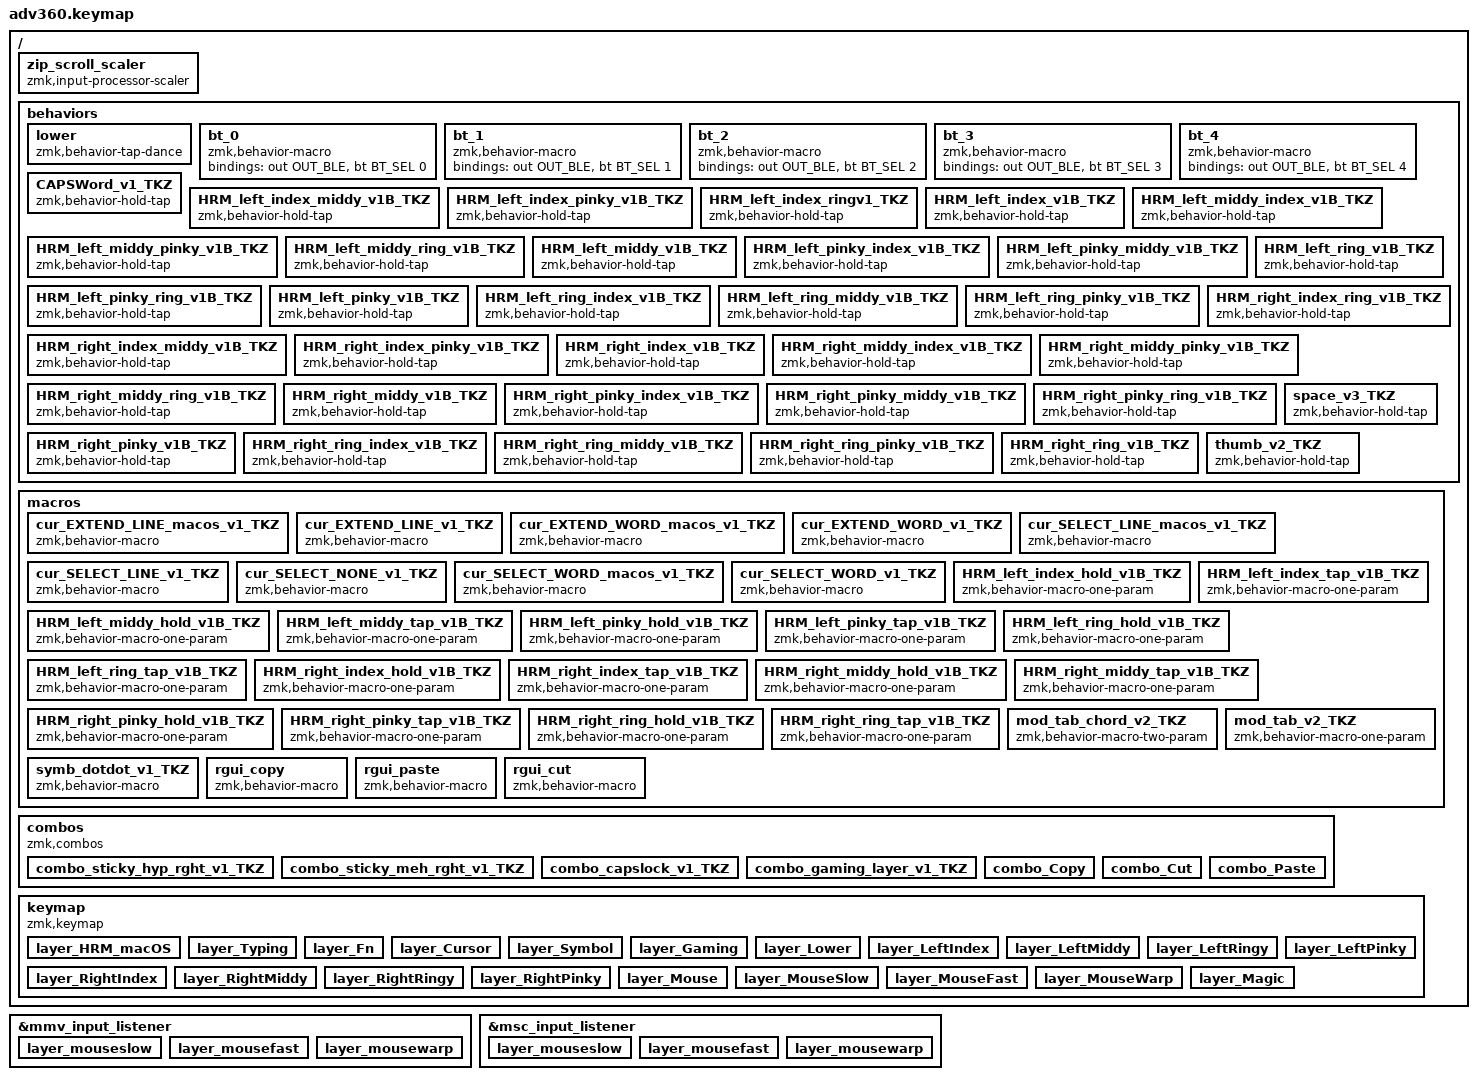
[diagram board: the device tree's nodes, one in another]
/*
 * GENERATED by scripts/glove80_to_adv360.py from "TailorKey v4.2i - macOS Bilateral but my".
 * Do not edit by hand: change the Glove80 layout or the script and regenerate.
 */

#include <behaviors.dtsi>
#include <input/processors.dtsi>
#include <dt-bindings/zmk/keys.h>
#include <dt-bindings/zmk/bt.h>
#include <dt-bindings/zmk/outputs.h>
#include <dt-bindings/zmk/rgb.h>
#include <dt-bindings/zmk/backlight.h>
#include <dt-bindings/zmk/pointing.h>
#include <dt-bindings/zmk/stp.h>

/ {
    /* MoErgo-only; Kinesis's ZMK has the x/y scalers but no scroll scaler. */
    /omit-if-no-ref/ zip_scroll_scaler: zip_scroll_scaler {
        compatible = "zmk,input-processor-scaler";
        #input-processor-cells = <2>;
        type = <INPUT_EV_REL>;
        codes = <INPUT_REL_WHEEL INPUT_REL_HWHEEL>;
        track-remainders;
    };
};

&mmv_input_listener {
    layer_mouseslow {
        layers = <16>;
        input-processors = <&zip_xy_scaler 1 9>;
    };
    layer_mousefast {
        layers = <17>;
        input-processors = <&zip_xy_scaler 3 1>;
    };
    layer_mousewarp {
        layers = <18>;
        input-processors = <&zip_xy_scaler 12 1>;
    };
};
&msc_input_listener {
    layer_mouseslow {
        layers = <16>;
        input-processors = <&zip_scroll_scaler 1 9>;
    };
    layer_mousefast {
        layers = <17>;
        input-processors = <&zip_scroll_scaler 3 1>;
    };
    layer_mousewarp {
        layers = <18>;
        input-processors = <&zip_scroll_scaler 12 1>;
    };
};

/ {
    behaviors {
        lower: lower {
            compatible = "zmk,behavior-tap-dance";
            #binding-cells = <0>;
            tapping-term-ms = <200>;
            bindings = <&mo 6>, <&to 6>;
        };
        bt_0: bt_0 {
            compatible = "zmk,behavior-macro";
            #binding-cells = <0>;
            bindings = <&out OUT_BLE>, <&bt BT_SEL 0>;
        };
        bt_1: bt_1 {
            compatible = "zmk,behavior-macro";
            #binding-cells = <0>;
            bindings = <&out OUT_BLE>, <&bt BT_SEL 1>;
        };
        bt_2: bt_2 {
            compatible = "zmk,behavior-macro";
            #binding-cells = <0>;
            bindings = <&out OUT_BLE>, <&bt BT_SEL 2>;
        };
        bt_3: bt_3 {
            compatible = "zmk,behavior-macro";
            #binding-cells = <0>;
            bindings = <&out OUT_BLE>, <&bt BT_SEL 3>;
        };
        bt_4: bt_4 {
            compatible = "zmk,behavior-macro";
            #binding-cells = <0>;
            bindings = <&out OUT_BLE>, <&bt BT_SEL 4>;
        };
        CAPSWord_v1_TKZ: CAPSWord_v1_TKZ {
            compatible = "zmk,behavior-hold-tap";
            #binding-cells = <2>;
            bindings = <&kp>, <&caps_word>;
            tapping-term-ms = <200>;
        };
        HRM_left_index_middy_v1B_TKZ: HRM_left_index_middy_v1B_TKZ {
            compatible = "zmk,behavior-hold-tap";
            #binding-cells = <2>;
            bindings = <&kp>, <&HRM_left_index_tap_v1B_TKZ>;
            tapping-term-ms = <190>;
            flavor = "tap-preferred";
            quick-tap-ms = <300>;
            require-prior-idle-ms = <100>;
            hold-trigger-on-release;
            hold-trigger-key-positions = <7 8 9 10 11 12 13 21 22 23 24 25 26 27 35 36 37 38 39 40 41 42 43 44 45 52 53 54 55 56 57 58 59 65 66 67 68 69 70 71 72 73 74 75>;
        };
        HRM_left_index_pinky_v1B_TKZ: HRM_left_index_pinky_v1B_TKZ {
            compatible = "zmk,behavior-hold-tap";
            #binding-cells = <2>;
            bindings = <&kp>, <&HRM_left_index_tap_v1B_TKZ>;
            tapping-term-ms = <190>;
            flavor = "tap-preferred";
            quick-tap-ms = <300>;
            require-prior-idle-ms = <100>;
            hold-trigger-on-release;
            hold-trigger-key-positions = <7 8 9 10 11 12 13 21 22 23 24 25 26 27 35 36 37 38 39 40 41 42 43 44 45 52 53 54 55 56 57 58 59 65 66 67 68 69 70 71 72 73 74 75>;
        };
        HRM_left_index_ringv1_TKZ: HRM_left_index_ringv1_TKZ {
            compatible = "zmk,behavior-hold-tap";
            #binding-cells = <2>;
            bindings = <&kp>, <&HRM_left_index_tap_v1B_TKZ>;
            tapping-term-ms = <190>;
            flavor = "tap-preferred";
            quick-tap-ms = <300>;
            require-prior-idle-ms = <100>;
            hold-trigger-on-release;
            hold-trigger-key-positions = <7 8 9 10 11 12 13 21 22 23 24 25 26 27 35 36 37 38 39 40 41 42 43 44 45 52 53 54 55 56 57 58 59 65 66 67 68 69 70 71 72 73 74 75>;
        };
        HRM_left_index_v1B_TKZ: HRM_left_index_v1B_TKZ {
            compatible = "zmk,behavior-hold-tap";
            #binding-cells = <2>;
            bindings = <&HRM_left_index_hold_v1B_TKZ>, <&kp>;
            tapping-term-ms = <190>;
            flavor = "tap-preferred";
            quick-tap-ms = <300>;
            require-prior-idle-ms = <100>;
            hold-trigger-on-release;
            hold-trigger-key-positions = <7 8 9 10 11 12 13 21 22 23 24 25 26 27 35 36 37 38 39 40 41 42 43 44 45 52 53 54 55 56 57 58 59 65 66 67 68 69 70 71 72 73 74 75>;
        };
        HRM_left_middy_index_v1B_TKZ: HRM_left_middy_index_v1B_TKZ {
            compatible = "zmk,behavior-hold-tap";
            #binding-cells = <2>;
            bindings = <&kp>, <&HRM_left_middy_tap_v1B_TKZ>;
            tapping-term-ms = <210>;
            flavor = "tap-preferred";
            quick-tap-ms = <300>;
            require-prior-idle-ms = <150>;
            hold-trigger-on-release;
            hold-trigger-key-positions = <7 8 9 10 11 12 13 21 22 23 24 25 26 27 35 36 37 38 39 40 41 42 43 44 45 52 53 54 55 56 57 58 59 65 66 67 68 69 70 71 72 73 74 75>;
        };
        HRM_left_middy_pinky_v1B_TKZ: HRM_left_middy_pinky_v1B_TKZ {
            compatible = "zmk,behavior-hold-tap";
            #binding-cells = <2>;
            bindings = <&kp>, <&HRM_left_middy_tap_v1B_TKZ>;
            tapping-term-ms = <210>;
            flavor = "tap-preferred";
            quick-tap-ms = <300>;
            require-prior-idle-ms = <150>;
            hold-trigger-on-release;
            hold-trigger-key-positions = <7 8 9 10 11 12 13 21 22 23 24 25 26 27 35 36 37 38 39 40 41 42 43 44 45 52 53 54 55 56 57 58 59 65 66 67 68 69 70 71 72 73 74 75>;
        };
        HRM_left_middy_ring_v1B_TKZ: HRM_left_middy_ring_v1B_TKZ {
            compatible = "zmk,behavior-hold-tap";
            #binding-cells = <2>;
            bindings = <&kp>, <&HRM_left_middy_tap_v1B_TKZ>;
            tapping-term-ms = <210>;
            flavor = "tap-preferred";
            quick-tap-ms = <300>;
            require-prior-idle-ms = <150>;
            hold-trigger-on-release;
            hold-trigger-key-positions = <7 8 9 10 11 12 13 21 22 23 24 25 26 27 35 36 37 38 39 40 41 42 43 44 45 52 53 54 55 56 57 58 59 65 66 67 68 69 70 71 72 73 74 75>;
        };
        HRM_left_middy_v1B_TKZ: HRM_left_middy_v1B_TKZ {
            compatible = "zmk,behavior-hold-tap";
            #binding-cells = <2>;
            bindings = <&HRM_left_middy_hold_v1B_TKZ>, <&kp>;
            tapping-term-ms = <210>;
            flavor = "tap-preferred";
            quick-tap-ms = <300>;
            require-prior-idle-ms = <150>;
            hold-trigger-on-release;
            hold-trigger-key-positions = <7 8 9 10 11 12 13 21 22 23 24 25 26 27 35 36 37 38 39 40 41 42 43 44 45 52 53 54 55 56 57 58 59 65 66 67 68 69 70 71 72 73 74 75>;
        };
        HRM_left_pinky_index_v1B_TKZ: HRM_left_pinky_index_v1B_TKZ {
            compatible = "zmk,behavior-hold-tap";
            #binding-cells = <2>;
            bindings = <&kp>, <&HRM_left_pinky_tap_v1B_TKZ>;
            tapping-term-ms = <280>;
            flavor = "tap-preferred";
            quick-tap-ms = <300>;
            require-prior-idle-ms = <150>;
            hold-trigger-on-release;
            hold-trigger-key-positions = <7 8 9 10 11 12 13 21 22 23 24 25 26 27 35 36 37 38 39 40 41 42 43 44 45 52 53 54 55 56 57 58 59 65 66 67 68 69 70 71 72 73 74 75>;
        };
        HRM_left_pinky_middy_v1B_TKZ: HRM_left_pinky_middy_v1B_TKZ {
            compatible = "zmk,behavior-hold-tap";
            #binding-cells = <2>;
            bindings = <&kp>, <&HRM_left_pinky_tap_v1B_TKZ>;
            tapping-term-ms = <280>;
            flavor = "tap-preferred";
            quick-tap-ms = <300>;
            require-prior-idle-ms = <150>;
            hold-trigger-on-release;
            hold-trigger-key-positions = <7 8 9 10 11 12 13 21 22 23 24 25 26 27 35 36 37 38 39 40 41 42 43 44 45 52 53 54 55 56 57 58 59 65 66 67 68 69 70 71 72 73 74 75>;
        };
        HRM_left_pinky_ring_v1B_TKZ: HRM_left_pinky_ring_v1B_TKZ {
            compatible = "zmk,behavior-hold-tap";
            #binding-cells = <2>;
            bindings = <&kp>, <&HRM_left_pinky_tap_v1B_TKZ>;
            tapping-term-ms = <280>;
            flavor = "tap-preferred";
            quick-tap-ms = <300>;
            require-prior-idle-ms = <150>;
            hold-trigger-on-release;
            hold-trigger-key-positions = <7 8 9 10 11 12 13 21 22 23 24 25 26 27 35 36 37 38 39 40 41 42 43 44 45 52 53 54 55 56 57 58 59 65 66 67 68 69 70 71 72 73 74 75>;
        };
        HRM_left_pinky_v1B_TKZ: HRM_left_pinky_v1B_TKZ {
            compatible = "zmk,behavior-hold-tap";
            #binding-cells = <2>;
            bindings = <&HRM_left_pinky_hold_v1B_TKZ>, <&kp>;
            tapping-term-ms = <280>;
            flavor = "tap-preferred";
            quick-tap-ms = <300>;
            require-prior-idle-ms = <150>;
            hold-trigger-on-release;
            hold-trigger-key-positions = <7 8 9 10 11 12 13 21 22 23 24 25 26 27 35 36 37 38 39 40 41 42 43 44 45 52 53 54 55 56 57 58 59 65 66 67 68 69 70 71 72 73 74 75>;
        };
        HRM_left_ring_index_v1B_TKZ: HRM_left_ring_index_v1B_TKZ {
            compatible = "zmk,behavior-hold-tap";
            #binding-cells = <2>;
            bindings = <&kp>, <&HRM_left_ring_tap_v1B_TKZ>;
            tapping-term-ms = <240>;
            flavor = "tap-preferred";
            quick-tap-ms = <300>;
            require-prior-idle-ms = <100>;
            hold-trigger-on-release;
            hold-trigger-key-positions = <7 8 9 10 11 12 13 21 22 23 24 25 26 27 35 36 37 38 39 40 41 42 43 44 45 52 53 54 55 56 57 58 59 65 66 67 68 69 70 71 72 73 74 75>;
        };
        HRM_left_ring_middy_v1B_TKZ: HRM_left_ring_middy_v1B_TKZ {
            compatible = "zmk,behavior-hold-tap";
            #binding-cells = <2>;
            bindings = <&kp>, <&HRM_left_ring_tap_v1B_TKZ>;
            tapping-term-ms = <240>;
            flavor = "tap-preferred";
            quick-tap-ms = <300>;
            require-prior-idle-ms = <150>;
            hold-trigger-on-release;
            hold-trigger-key-positions = <7 8 9 10 11 12 13 21 22 23 24 25 26 27 35 36 37 38 39 40 41 42 43 44 45 52 53 54 55 56 57 58 59 65 66 67 68 69 70 71 72 73 74 75>;
        };
        HRM_left_ring_pinky_v1B_TKZ: HRM_left_ring_pinky_v1B_TKZ {
            compatible = "zmk,behavior-hold-tap";
            #binding-cells = <2>;
            bindings = <&kp>, <&HRM_left_ring_tap_v1B_TKZ>;
            tapping-term-ms = <240>;
            flavor = "tap-preferred";
            quick-tap-ms = <300>;
            require-prior-idle-ms = <150>;
            hold-trigger-on-release;
            hold-trigger-key-positions = <7 8 9 10 11 12 13 21 22 23 24 25 26 27 35 36 37 38 39 40 41 42 43 44 45 52 53 54 55 56 57 58 59 65 66 67 68 69 70 71 72 73 74 75>;
        };
        HRM_left_ring_v1B_TKZ: HRM_left_ring_v1B_TKZ {
            compatible = "zmk,behavior-hold-tap";
            #binding-cells = <2>;
            bindings = <&HRM_left_ring_hold_v1B_TKZ>, <&kp>;
            tapping-term-ms = <240>;
            flavor = "tap-preferred";
            quick-tap-ms = <300>;
            require-prior-idle-ms = <150>;
            hold-trigger-on-release;
            hold-trigger-key-positions = <7 8 9 10 11 12 13 21 22 23 24 25 26 27 35 36 37 38 39 40 41 42 43 44 45 52 53 54 55 56 57 58 59 65 66 67 68 69 70 71 72 73 74 75>;
        };
        HRM_right_index_middy_v1B_TKZ: HRM_right_index_middy_v1B_TKZ {
            compatible = "zmk,behavior-hold-tap";
            #binding-cells = <2>;
            bindings = <&kp>, <&HRM_right_index_tap_v1B_TKZ>;
            tapping-term-ms = <190>;
            flavor = "tap-preferred";
            quick-tap-ms = <300>;
            require-prior-idle-ms = <100>;
            hold-trigger-on-release;
            hold-trigger-key-positions = <0 1 2 3 4 5 6 14 15 16 17 18 19 20 28 29 30 31 32 33 34 35 36 37 38 46 47 48 49 50 51 52 53 60 61 62 63 64 65 66 67 68 69 70>;
        };
        HRM_right_index_pinky_v1B_TKZ: HRM_right_index_pinky_v1B_TKZ {
            compatible = "zmk,behavior-hold-tap";
            #binding-cells = <2>;
            bindings = <&kp>, <&HRM_right_index_tap_v1B_TKZ>;
            tapping-term-ms = <190>;
            flavor = "tap-preferred";
            quick-tap-ms = <300>;
            require-prior-idle-ms = <100>;
            hold-trigger-on-release;
            hold-trigger-key-positions = <0 1 2 3 4 5 6 14 15 16 17 18 19 20 28 29 30 31 32 33 34 35 36 37 38 46 47 48 49 50 51 52 53 60 61 62 63 64 65 66 67 68 69 70>;
        };
        HRM_right_index_ring_v1B_TKZ: HRM_right_index_ring_v1B_TKZ {
            compatible = "zmk,behavior-hold-tap";
            #binding-cells = <2>;
            bindings = <&kp>, <&HRM_right_index_tap_v1B_TKZ>;
            tapping-term-ms = <190>;
            flavor = "tap-preferred";
            quick-tap-ms = <300>;
            require-prior-idle-ms = <100>;
            hold-trigger-on-release;
            hold-trigger-key-positions = <0 1 2 3 4 5 6 14 15 16 17 18 19 20 28 29 30 31 32 33 34 35 36 37 38 46 47 48 49 50 51 52 53 60 61 62 63 64 65 66 67 68 69 70>;
        };
        HRM_right_index_v1B_TKZ: HRM_right_index_v1B_TKZ {
            compatible = "zmk,behavior-hold-tap";
            #binding-cells = <2>;
            bindings = <&HRM_right_index_hold_v1B_TKZ>, <&kp>;
            tapping-term-ms = <190>;
            flavor = "tap-preferred";
            quick-tap-ms = <300>;
            require-prior-idle-ms = <100>;
            hold-trigger-on-release;
            hold-trigger-key-positions = <0 1 2 3 4 5 6 14 15 16 17 18 19 20 28 29 30 31 32 33 34 35 36 37 38 46 47 48 49 50 51 52 53 60 61 62 63 64 65 66 67 68 69 70>;
        };
        HRM_right_middy_index_v1B_TKZ: HRM_right_middy_index_v1B_TKZ {
            compatible = "zmk,behavior-hold-tap";
            #binding-cells = <2>;
            bindings = <&kp>, <&HRM_right_middy_tap_v1B_TKZ>;
            tapping-term-ms = <210>;
            flavor = "tap-preferred";
            quick-tap-ms = <300>;
            require-prior-idle-ms = <150>;
            hold-trigger-on-release;
            hold-trigger-key-positions = <0 1 2 3 4 5 6 14 15 16 17 18 19 20 28 29 30 31 32 33 34 35 36 37 38 46 47 48 49 50 51 52 53 60 61 62 63 64 65 66 67 68 69 70>;
        };
        HRM_right_middy_pinky_v1B_TKZ: HRM_right_middy_pinky_v1B_TKZ {
            compatible = "zmk,behavior-hold-tap";
            #binding-cells = <2>;
            bindings = <&kp>, <&HRM_right_middy_tap_v1B_TKZ>;
            tapping-term-ms = <210>;
            flavor = "tap-preferred";
            quick-tap-ms = <300>;
            require-prior-idle-ms = <150>;
            hold-trigger-on-release;
            hold-trigger-key-positions = <0 1 2 3 4 5 6 14 15 16 17 18 19 20 28 29 30 31 32 33 34 35 36 37 38 46 47 48 49 50 51 52 53 60 61 62 63 64 65 66 67 68 69 70>;
        };
        HRM_right_middy_ring_v1B_TKZ: HRM_right_middy_ring_v1B_TKZ {
            compatible = "zmk,behavior-hold-tap";
            #binding-cells = <2>;
            bindings = <&kp>, <&HRM_right_middy_tap_v1B_TKZ>;
            tapping-term-ms = <210>;
            flavor = "tap-preferred";
            quick-tap-ms = <300>;
            require-prior-idle-ms = <150>;
            hold-trigger-on-release;
            hold-trigger-key-positions = <0 1 2 3 4 5 6 14 15 16 17 18 19 20 28 29 30 31 32 33 34 35 36 37 38 46 47 48 49 50 51 52 53 60 61 62 63 64 65 66 67 68 69 70>;
        };
        HRM_right_middy_v1B_TKZ: HRM_right_middy_v1B_TKZ {
            compatible = "zmk,behavior-hold-tap";
            #binding-cells = <2>;
            bindings = <&HRM_right_middy_hold_v1B_TKZ>, <&kp>;
            tapping-term-ms = <210>;
            flavor = "tap-preferred";
            quick-tap-ms = <300>;
            require-prior-idle-ms = <150>;
            hold-trigger-on-release;
            hold-trigger-key-positions = <0 1 2 3 4 5 6 14 15 16 17 18 19 20 28 29 30 31 32 33 34 35 36 37 38 46 47 48 49 50 51 52 53 60 61 62 63 64 65 66 67 68 69 70>;
        };
        HRM_right_pinky_index_v1B_TKZ: HRM_right_pinky_index_v1B_TKZ {
            compatible = "zmk,behavior-hold-tap";
            #binding-cells = <2>;
            bindings = <&kp>, <&HRM_right_pinky_tap_v1B_TKZ>;
            tapping-term-ms = <280>;
            flavor = "tap-preferred";
            quick-tap-ms = <300>;
            require-prior-idle-ms = <150>;
            hold-trigger-on-release;
            hold-trigger-key-positions = <0 1 2 3 4 5 6 14 15 16 17 18 19 20 28 29 30 31 32 33 34 35 36 37 38 46 47 48 49 50 51 52 53 60 61 62 63 64 65 66 67 68 69 70>;
        };
        HRM_right_pinky_middy_v1B_TKZ: HRM_right_pinky_middy_v1B_TKZ {
            compatible = "zmk,behavior-hold-tap";
            #binding-cells = <2>;
            bindings = <&kp>, <&HRM_right_pinky_tap_v1B_TKZ>;
            tapping-term-ms = <280>;
            flavor = "tap-preferred";
            quick-tap-ms = <300>;
            require-prior-idle-ms = <150>;
            hold-trigger-on-release;
            hold-trigger-key-positions = <0 1 2 3 4 5 6 14 15 16 17 18 19 20 28 29 30 31 32 33 34 35 36 37 38 46 47 48 49 50 51 52 53 60 61 62 63 64 65 66 67 68 69 70>;
        };
        HRM_right_pinky_ring_v1B_TKZ: HRM_right_pinky_ring_v1B_TKZ {
            compatible = "zmk,behavior-hold-tap";
            #binding-cells = <2>;
            bindings = <&kp>, <&HRM_right_pinky_tap_v1B_TKZ>;
            tapping-term-ms = <280>;
            flavor = "tap-preferred";
            quick-tap-ms = <300>;
            require-prior-idle-ms = <150>;
            hold-trigger-on-release;
            hold-trigger-key-positions = <0 1 2 3 4 5 6 14 15 16 17 18 19 20 28 29 30 31 32 33 34 35 36 37 38 46 47 48 49 50 51 52 53 60 61 62 63 64 65 66 67 68 69 70>;
        };
        HRM_right_pinky_v1B_TKZ: HRM_right_pinky_v1B_TKZ {
            compatible = "zmk,behavior-hold-tap";
            #binding-cells = <2>;
            bindings = <&HRM_right_pinky_hold_v1B_TKZ>, <&kp>;
            tapping-term-ms = <280>;
            flavor = "tap-preferred";
            quick-tap-ms = <300>;
            require-prior-idle-ms = <150>;
            hold-trigger-on-release;
            hold-trigger-key-positions = <0 1 2 3 4 5 6 14 15 16 17 18 19 20 28 29 30 31 32 33 34 35 36 37 38 46 47 48 49 50 51 52 53 60 61 62 63 64 65 66 67 68 69 70>;
        };
        HRM_right_ring_index_v1B_TKZ: HRM_right_ring_index_v1B_TKZ {
            compatible = "zmk,behavior-hold-tap";
            #binding-cells = <2>;
            bindings = <&kp>, <&HRM_right_ring_tap_v1B_TKZ>;
            tapping-term-ms = <240>;
            flavor = "tap-preferred";
            quick-tap-ms = <300>;
            require-prior-idle-ms = <150>;
            hold-trigger-on-release;
            hold-trigger-key-positions = <0 1 2 3 4 5 6 14 15 16 17 18 19 20 28 29 30 31 32 33 34 35 36 37 38 46 47 48 49 50 51 52 53 60 61 62 63 64 65 66 67 68 69 70>;
        };
        HRM_right_ring_middy_v1B_TKZ: HRM_right_ring_middy_v1B_TKZ {
            compatible = "zmk,behavior-hold-tap";
            #binding-cells = <2>;
            bindings = <&kp>, <&HRM_right_ring_tap_v1B_TKZ>;
            tapping-term-ms = <240>;
            flavor = "tap-preferred";
            quick-tap-ms = <300>;
            require-prior-idle-ms = <150>;
            hold-trigger-on-release;
            hold-trigger-key-positions = <0 1 2 3 4 5 6 14 15 16 17 18 19 20 28 29 30 31 32 33 34 35 36 37 38 46 47 48 49 50 51 52 53 60 61 62 63 64 65 66 67 68 69 70>;
        };
        HRM_right_ring_pinky_v1B_TKZ: HRM_right_ring_pinky_v1B_TKZ {
            compatible = "zmk,behavior-hold-tap";
            #binding-cells = <2>;
            bindings = <&kp>, <&HRM_right_ring_tap_v1B_TKZ>;
            tapping-term-ms = <240>;
            flavor = "tap-preferred";
            quick-tap-ms = <300>;
            require-prior-idle-ms = <150>;
            hold-trigger-on-release;
            hold-trigger-key-positions = <0 1 2 3 4 5 6 14 15 16 17 18 19 20 28 29 30 31 32 33 34 35 36 37 38 46 47 48 49 50 51 52 53 60 61 62 63 64 65 66 67 68 69 70>;
        };
        HRM_right_ring_v1B_TKZ: HRM_right_ring_v1B_TKZ {
            compatible = "zmk,behavior-hold-tap";
            #binding-cells = <2>;
            bindings = <&HRM_right_ring_hold_v1B_TKZ>, <&kp>;
            tapping-term-ms = <240>;
            flavor = "tap-preferred";
            quick-tap-ms = <300>;
            require-prior-idle-ms = <150>;
            hold-trigger-on-release;
            hold-trigger-key-positions = <0 1 2 3 4 5 6 14 15 16 17 18 19 20 28 29 30 31 32 33 34 35 36 37 38 46 47 48 49 50 51 52 53 60 61 62 63 64 65 66 67 68 69 70>;
        };
        space_v3_TKZ: space_v3_TKZ {
            compatible = "zmk,behavior-hold-tap";
            #binding-cells = <2>;
            bindings = <&mo>, <&kp>;
            tapping-term-ms = <200>;
            flavor = "balanced";
            quick-tap-ms = <150>;
        };
        thumb_v2_TKZ: thumb_v2_TKZ {
            compatible = "zmk,behavior-hold-tap";
            #binding-cells = <2>;
            bindings = <&mo>, <&kp>;
            tapping-term-ms = <200>;
            flavor = "balanced";
            quick-tap-ms = <300>;
        };
    };

    macros {
        cur_EXTEND_LINE_macos_v1_TKZ: cur_EXTEND_LINE_macos_v1_TKZ {
            compatible = "zmk,behavior-macro";
            #binding-cells = <0>;
            wait-ms = <1>;
            tap-ms = <1>;
            bindings = <&kp LG(LS(RIGHT))>;
        };
        cur_EXTEND_LINE_v1_TKZ: cur_EXTEND_LINE_v1_TKZ {
            compatible = "zmk,behavior-macro";
            #binding-cells = <0>;
            wait-ms = <1>;
            tap-ms = <1>;
            bindings = <&kp LS(END)>;
        };
        cur_EXTEND_WORD_macos_v1_TKZ: cur_EXTEND_WORD_macos_v1_TKZ {
            compatible = "zmk,behavior-macro";
            #binding-cells = <0>;
            wait-ms = <1>;
            tap-ms = <1>;
            bindings = <&kp LA(LS(RIGHT))>;
        };
        cur_EXTEND_WORD_v1_TKZ: cur_EXTEND_WORD_v1_TKZ {
            compatible = "zmk,behavior-macro";
            #binding-cells = <0>;
            wait-ms = <1>;
            tap-ms = <1>;
            bindings = <&kp LC(LS(RIGHT))>;
        };
        cur_SELECT_LINE_macos_v1_TKZ: cur_SELECT_LINE_macos_v1_TKZ {
            compatible = "zmk,behavior-macro";
            #binding-cells = <0>;
            wait-ms = <1>;
            tap-ms = <1>;
            bindings = <&kp LG(LEFT)>, <&kp LG(LS(RIGHT))>;
        };
        cur_SELECT_LINE_v1_TKZ: cur_SELECT_LINE_v1_TKZ {
            compatible = "zmk,behavior-macro";
            #binding-cells = <0>;
            wait-ms = <1>;
            tap-ms = <1>;
            bindings = <&kp HOME>, <&kp LS(END)>;
        };
        cur_SELECT_NONE_v1_TKZ: cur_SELECT_NONE_v1_TKZ {
            compatible = "zmk,behavior-macro";
            #binding-cells = <0>;
            wait-ms = <1>;
            tap-ms = <1>;
            bindings = <&kp DOWN>, <&kp UP>, <&kp RIGHT>, <&kp LEFT>;
        };
        cur_SELECT_WORD_macos_v1_TKZ: cur_SELECT_WORD_macos_v1_TKZ {
            compatible = "zmk,behavior-macro";
            #binding-cells = <0>;
            wait-ms = <1>;
            tap-ms = <1>;
            bindings = <&kp LA(LEFT)>, <&kp LA(LS(RIGHT))>;
        };
        cur_SELECT_WORD_v1_TKZ: cur_SELECT_WORD_v1_TKZ {
            compatible = "zmk,behavior-macro";
            #binding-cells = <0>;
            wait-ms = <1>;
            tap-ms = <1>;
            bindings = <&kp LC(LEFT)>, <&kp LC(LS(RIGHT))>;
        };
        HRM_left_index_hold_v1B_TKZ: HRM_left_index_hold_v1B_TKZ {
            compatible = "zmk,behavior-macro-one-param";
            #binding-cells = <1>;
            wait-ms = <0>;
            tap-ms = <0>;
            bindings = <&macro_press>, <&macro_param_1to1>, <&kp A>, <&mo 7>, <&macro_pause_for_release>, <&macro_release>, <&macro_param_1to1>, <&kp A>, <&mo 7>;
        };
        HRM_left_index_tap_v1B_TKZ: HRM_left_index_tap_v1B_TKZ {
            compatible = "zmk,behavior-macro-one-param";
            #binding-cells = <1>;
            wait-ms = <0>;
            tap-ms = <0>;
            bindings = <&macro_release>, <&kp LSHFT>, <&kp RSHFT>, <&kp LALT>, <&kp RALT>, <&kp LCTRL>, <&kp RCTRL>, <&kp LGUI>, <&kp RGUI>, <&macro_tap>, <&kp F>, <&macro_tap>, <&macro_param_1to1>, <&kp A>;
        };
        HRM_left_middy_hold_v1B_TKZ: HRM_left_middy_hold_v1B_TKZ {
            compatible = "zmk,behavior-macro-one-param";
            #binding-cells = <1>;
            wait-ms = <0>;
            tap-ms = <0>;
            bindings = <&macro_press>, <&macro_param_1to1>, <&kp A>, <&mo 8>, <&macro_pause_for_release>, <&macro_release>, <&macro_param_1to1>, <&kp A>, <&mo 8>;
        };
        HRM_left_middy_tap_v1B_TKZ: HRM_left_middy_tap_v1B_TKZ {
            compatible = "zmk,behavior-macro-one-param";
            #binding-cells = <1>;
            wait-ms = <0>;
            tap-ms = <0>;
            bindings = <&macro_release>, <&kp LSHFT>, <&kp RSHFT>, <&kp LALT>, <&kp RALT>, <&kp LCTRL>, <&kp RCTRL>, <&kp LGUI>, <&kp RGUI>, <&macro_tap>, <&kp D>, <&macro_tap>, <&macro_param_1to1>, <&kp A>;
        };
        HRM_left_pinky_hold_v1B_TKZ: HRM_left_pinky_hold_v1B_TKZ {
            compatible = "zmk,behavior-macro-one-param";
            #binding-cells = <1>;
            wait-ms = <0>;
            tap-ms = <0>;
            bindings = <&macro_press>, <&macro_param_1to1>, <&kp A>, <&mo 10>, <&macro_pause_for_release>, <&macro_release>, <&macro_param_1to1>, <&kp A>, <&mo 10>;
        };
        HRM_left_pinky_tap_v1B_TKZ: HRM_left_pinky_tap_v1B_TKZ {
            compatible = "zmk,behavior-macro-one-param";
            #binding-cells = <1>;
            wait-ms = <0>;
            tap-ms = <0>;
            bindings = <&macro_release>, <&kp LSHFT>, <&kp RSHFT>, <&kp LALT>, <&kp RALT>, <&kp LCTRL>, <&kp RCTRL>, <&kp LGUI>, <&kp RGUI>, <&macro_tap>, <&kp A>, <&macro_tap>, <&macro_param_1to1>, <&kp A>;
        };
        HRM_left_ring_hold_v1B_TKZ: HRM_left_ring_hold_v1B_TKZ {
            compatible = "zmk,behavior-macro-one-param";
            #binding-cells = <1>;
            wait-ms = <0>;
            tap-ms = <0>;
            bindings = <&macro_press>, <&macro_param_1to1>, <&kp A>, <&mo 9>, <&macro_pause_for_release>, <&macro_release>, <&macro_param_1to1>, <&kp A>, <&mo 9>;
        };
        HRM_left_ring_tap_v1B_TKZ: HRM_left_ring_tap_v1B_TKZ {
            compatible = "zmk,behavior-macro-one-param";
            #binding-cells = <1>;
            wait-ms = <0>;
            tap-ms = <0>;
            bindings = <&macro_release>, <&kp LSHFT>, <&kp RSHFT>, <&kp LALT>, <&kp RALT>, <&kp LCTRL>, <&kp RCTRL>, <&kp LGUI>, <&kp RGUI>, <&macro_tap>, <&kp S>, <&macro_tap>, <&macro_param_1to1>, <&kp A>;
        };
        HRM_right_index_hold_v1B_TKZ: HRM_right_index_hold_v1B_TKZ {
            compatible = "zmk,behavior-macro-one-param";
            #binding-cells = <1>;
            wait-ms = <0>;
            tap-ms = <0>;
            bindings = <&macro_press>, <&macro_param_1to1>, <&kp A>, <&mo 11>, <&macro_pause_for_release>, <&macro_release>, <&macro_param_1to1>, <&kp A>, <&mo 11>;
        };
        HRM_right_index_tap_v1B_TKZ: HRM_right_index_tap_v1B_TKZ {
            compatible = "zmk,behavior-macro-one-param";
            #binding-cells = <1>;
            wait-ms = <0>;
            tap-ms = <0>;
            bindings = <&macro_release>, <&kp LSHFT>, <&kp RSHFT>, <&kp LALT>, <&kp RALT>, <&kp LCTRL>, <&kp RCTRL>, <&kp LGUI>, <&kp RGUI>, <&macro_tap>, <&kp J>, <&macro_tap>, <&macro_param_1to1>, <&kp A>;
        };
        HRM_right_middy_hold_v1B_TKZ: HRM_right_middy_hold_v1B_TKZ {
            compatible = "zmk,behavior-macro-one-param";
            #binding-cells = <1>;
            wait-ms = <0>;
            tap-ms = <0>;
            bindings = <&macro_press>, <&macro_param_1to1>, <&kp A>, <&mo 12>, <&macro_pause_for_release>, <&macro_release>, <&macro_param_1to1>, <&kp A>, <&mo 12>;
        };
        HRM_right_middy_tap_v1B_TKZ: HRM_right_middy_tap_v1B_TKZ {
            compatible = "zmk,behavior-macro-one-param";
            #binding-cells = <1>;
            wait-ms = <0>;
            tap-ms = <0>;
            bindings = <&macro_release>, <&kp LSHFT>, <&kp RSHFT>, <&kp LALT>, <&kp RALT>, <&kp LCTRL>, <&kp RCTRL>, <&kp LGUI>, <&kp RGUI>, <&macro_tap>, <&kp K>, <&macro_tap>, <&macro_param_1to1>, <&kp A>;
        };
        HRM_right_pinky_hold_v1B_TKZ: HRM_right_pinky_hold_v1B_TKZ {
            compatible = "zmk,behavior-macro-one-param";
            #binding-cells = <1>;
            wait-ms = <0>;
            tap-ms = <0>;
            bindings = <&macro_press>, <&macro_param_1to1>, <&kp A>, <&mo 14>, <&macro_pause_for_release>, <&macro_release>, <&macro_param_1to1>, <&kp A>, <&mo 14>;
        };
        HRM_right_pinky_tap_v1B_TKZ: HRM_right_pinky_tap_v1B_TKZ {
            compatible = "zmk,behavior-macro-one-param";
            #binding-cells = <1>;
            wait-ms = <0>;
            tap-ms = <0>;
            bindings = <&macro_release>, <&kp LSHFT>, <&kp RSHFT>, <&kp LALT>, <&kp RALT>, <&kp LCTRL>, <&kp RCTRL>, <&kp LGUI>, <&kp RGUI>, <&macro_tap>, <&kp SEMI>, <&macro_tap>, <&macro_param_1to1>, <&kp A>;
        };
        HRM_right_ring_hold_v1B_TKZ: HRM_right_ring_hold_v1B_TKZ {
            compatible = "zmk,behavior-macro-one-param";
            #binding-cells = <1>;
            wait-ms = <0>;
            tap-ms = <0>;
            bindings = <&macro_press>, <&macro_param_1to1>, <&kp A>, <&mo 13>, <&macro_pause_for_release>, <&macro_release>, <&macro_param_1to1>, <&kp A>, <&mo 13>;
        };
        HRM_right_ring_tap_v1B_TKZ: HRM_right_ring_tap_v1B_TKZ {
            compatible = "zmk,behavior-macro-one-param";
            #binding-cells = <1>;
            wait-ms = <0>;
            tap-ms = <0>;
            bindings = <&macro_release>, <&kp LSHFT>, <&kp RSHFT>, <&kp LALT>, <&kp RALT>, <&kp LCTRL>, <&kp RCTRL>, <&kp LGUI>, <&kp RGUI>, <&macro_tap>, <&kp L>, <&macro_tap>, <&macro_param_1to1>, <&kp A>;
        };
        mod_tab_chord_v2_TKZ: mod_tab_chord_v2_TKZ {
            compatible = "zmk,behavior-macro-two-param";
            #binding-cells = <2>;
            wait-ms = <0>;
            tap-ms = <0>;
            bindings = <&macro_press>, <&macro_param_2to1>, <&mo 0>, <&macro_press>, <&macro_param_1to1>, <&mod_tab_v2_TKZ 0>, <&macro_pause_for_release>, <&macro_release>, <&macro_param_1to1>, <&mod_tab_v2_TKZ 0>, <&macro_release>, <&macro_param_2to1>, <&mo 0>;
        };
        mod_tab_v2_TKZ: mod_tab_v2_TKZ {
            compatible = "zmk,behavior-macro-one-param";
            #binding-cells = <1>;
            wait-ms = <0>;
            tap-ms = <0>;
            bindings = <&macro_press>, <&macro_param_1to1>, <&kp 0>, <&macro_tap>, <&kp TAB>, <&macro_pause_for_release>, <&macro_release>, <&macro_param_1to1>, <&kp 0>;
        };
        symb_dotdot_v1_TKZ: symb_dotdot_v1_TKZ {
            compatible = "zmk,behavior-macro";
            #binding-cells = <0>;
            wait-ms = <0>;
            tap-ms = <0>;
            bindings = <&macro_tap>, <&kp DOT>, <&kp DOT>;
        };
        rgui_copy: rgui_copy {
            compatible = "zmk,behavior-macro";
            #binding-cells = <0>;
            bindings = <&macro_press>, <&kp RGUI>, <&macro_tap>, <&kp C>, <&macro_release>, <&kp RGUI>;
        };
        rgui_paste: rgui_paste {
            compatible = "zmk,behavior-macro";
            #binding-cells = <0>;
            bindings = <&macro_press>, <&kp RGUI>, <&macro_tap>, <&kp V>, <&macro_release>, <&kp RGUI>;
        };
        rgui_cut: rgui_cut {
            compatible = "zmk,behavior-macro";
            #binding-cells = <0>;
            bindings = <&macro_press>, <&kp RGUI>, <&macro_tap>, <&kp X>, <&macro_release>, <&kp RGUI>;
        };
    };

    combos {
        compatible = "zmk,combos";
        combo_sticky_hyp_rght_v1_TKZ {
            bindings = <&sk LG(LA(LC(LSHFT)))>;
            key-positions = <38 70>;
            timeout-ms = <50>;
            layers = <0>;
        };
        combo_sticky_meh_rght_v1_TKZ {
            bindings = <&sk LA(LC(LSHFT))>;
            key-positions = <69 70>;
            timeout-ms = <50>;
            layers = <0>;
        };
        combo_capslock_v1_TKZ {
            bindings = <&kp CAPS>;
            key-positions = <35 38>;
            timeout-ms = <50>;
            layers = <0>;
        };
        combo_gaming_layer_v1_TKZ {
            bindings = <&tog 5>;
            key-positions = <51 64>;
            timeout-ms = <50>;
        };
        combo_Copy {
            bindings = <&rgui_copy>;
            key-positions = <48 49>;
            timeout-ms = <50>;
        };
        combo_Cut {
            bindings = <&rgui_cut>;
            key-positions = <48 50>;
            timeout-ms = <50>;
        };
        combo_Paste {
            bindings = <&rgui_paste>;
            key-positions = <49 50>;
            timeout-ms = <50>;
        };
    };

    keymap {
        compatible = "zmk,keymap";
        layer_HRM_macOS {
            display-name = "HRM_macOS";
            bindings = <
            &kp EQUAL  &kp N1  &kp N2  &kp N3  &kp N4  &kp N5  &kp C_PREV  &kp C_VOL_UP  &kp N6  &kp N7  &kp N8  &kp N9  &kp N0  &kp MINUS
            &kp ESC  &kp Q  &kp W  &kp E  &kp R  &kp T  &kp C_PP  &kp C_VOL_DN  &kp Y  &kp U  &kp I  &kp O  &kp P  &kp EQUAL
            &kp TAB  &HRM_left_pinky_v1B_TKZ LCTRL A  &HRM_left_ring_v1B_TKZ LALT S  &HRM_left_middy_v1B_TKZ LGUI D  &HRM_left_index_v1B_TKZ LSHFT F  &kp G  &kp C_NEXT  &CAPSWord_v1_TKZ LSHFT 0  &kp LGUI  &kp RGUI  &CAPSWord_v1_TKZ RSHFT 0  &kp C_MUTE  &kp H  &HRM_right_index_v1B_TKZ LSHFT J  &HRM_right_middy_v1B_TKZ LGUI K  &HRM_right_ring_v1B_TKZ LALT L  &HRM_right_pinky_v1B_TKZ LCTRL SEMI  &kp SQT
            &kp BSLH  &kp Z  &kp X  &kp C  &kp V  &kp B  &lower  &kp LCTRL  &kp N  &kp M  &kp COMMA  &kp DOT  &kp FSLH  &kp MINUS
            &mo 19  &kp HOME  &kp END  &kp LEFT  &kp RIGHT  &thumb_v2_TKZ 2 RET  &thumb_v2_TKZ 3 SPACE  &kp TAB  &kp ESC  &thumb_v2_TKZ 15 BSPC  &space_v3_TKZ 4 DEL  &kp UP  &kp DOWN  &kp LBKT  &kp RBKT  &kp GRAVE
            >;
        };
        layer_Typing {
            display-name = "Typing";
            bindings = <
            &trans  &trans  &trans  &trans  &trans  &trans  &trans  &trans  &trans  &trans  &trans  &trans  &trans  &trans
            &trans  &trans  &trans  &trans  &trans  &trans  &trans  &trans  &trans  &trans  &trans  &trans  &trans  &trans
            &trans  &kp A  &kp S  &kp D  &kp F  &trans  &trans  &trans  &trans  &trans  &trans  &trans  &trans  &kp J  &kp K  &kp L  &kp SEMI  &trans
            &trans  &trans  &trans  &trans  &trans  &trans  &trans  &trans  &trans  &trans  &trans  &trans  &trans  &trans
            &trans  &trans  &trans  &trans  &trans  &trans  &trans  &trans  &trans  &trans  &trans  &trans  &trans  &trans  &trans  &trans
            >;
        };
        layer_Fn {
            display-name = "Fn";
            bindings = <
            &none  &none  &none  &none  &none  &none  &none  &none  &none  &none  &none  &none  &none  &none
            &none  &none  &none  &none  &none  &none  &none  &none  &kp F12  &kp F7  &kp F8  &kp F9  &none  &none
            &none  &none  &none  &none  &none  &none  &none  &none  &none  &none  &none  &none  &kp F11  &kp F4  &kp F5  &kp F6  &none  &none
            &none  &none  &none  &none  &none  &none  &none  &none  &kp F10  &kp F1  &kp F2  &kp F3  &none  &none
            &none  &none  &none  &none  &none  &none  &none  &none  &none  &none  &none  &none  &none  &none  &none  &none
            >;
        };
        layer_Cursor {
            display-name = "Cursor";
            bindings = <
            &none  &kp ESC  &kp INS  &kp LS(TAB)  &kp DEL  &none  &none  &none  &none  &none  &none  &none  &none  &none
            &none  &kp RET  &kp SPACE  &kp TAB  &kp BSPC  &kp LG(X)  &none  &none  &kp LG(X)  &kp LS(TAB)  &kp LG(Z)  &kp LG(LS(Z))  &kp TAB  &none
            &sk LSHFT  &kp LCTRL  &kp LALT  &kp LGUI  &kp LSHFT  &kp LG(C)  &none  &mod_tab_v2_TKZ LGUI  &mod_tab_v2_TKZ LALT  &cur_EXTEND_LINE_macos_v1_TKZ  &cur_EXTEND_WORD_macos_v1_TKZ  &none  &kp LEFT  &kp DOWN  &kp UP  &kp RIGHT  &none  &sk RSHFT
            &kp LG(L)  &kp LG(A)  &cur_SELECT_LINE_macos_v1_TKZ  &cur_SELECT_WORD_macos_v1_TKZ  &kp LG(F)  &kp LG(V)  &kp PSCRN  &cur_SELECT_NONE_v1_TKZ  &kp LG(V)  &kp HOME  &kp PG_UP  &kp PG_DN  &kp END  &kp LG(L)
            &kp LG(K)  &kp LG(Z)  &kp LG(LS(Z))  &kp LG(LS(G))  &kp LG(G)  &none  &mod_tab_v2_TKZ LCTRL  &kp LG(F3)  &kp LG(A)  &cur_SELECT_LINE_macos_v1_TKZ  &cur_SELECT_WORD_macos_v1_TKZ  &kp LG(F)  &kp LG(LS(G))  &kp LG(G)  &kp LC(H)  &kp LG(K)
            >;
        };
        layer_Symbol {
            display-name = "Symbol";
            bindings = <
            &kp GRAVE  &kp COMMA  &kp LS(N9)  &kp LS(N0)  &kp SEMI  &kp DOT  &none  &none  &none  &none  &none  &none  &none  &none
            &kp LS(N1)  &kp LBKT  &kp LS(LBKT)  &kp LS(RBKT)  &kp RBKT  &kp LS(FSLH)  &none  &none  &kp GRAVE  &kp DEL  &kp LS(TAB)  &kp INS  &kp ESC  &none
            &kp LS(N3)  &kp LS(N6)  &kp EQUAL  &kp LS(MINUS)  &kp LS(N4)  &kp LS(N8)  &none  &kp BSLH  &kp DOT  &none  &none  &none  &kp LS(SINGLE_QUOTE)  &kp BSPC  &kp TAB  &kp SPACE  &kp RET  &none
            &kp LS(GRAVE)  &kp LS(COMMA)  &kp LS(BSLH)  &kp MINUS  &kp LS(DOT)  &kp FSLH  &kp LS(N8)  &none  &kp SQT  &sk RSHFT  &sk RCTRL  &sk RALT  &sk RGUI  &none
            &symb_dotdot_v1_TKZ  &kp LS(N7)  &kp SQT  &kp LS(SINGLE_QUOTE)  &kp LS(EQUAL)  &kp LS(N5)  &kp LS(SEMI)  &kp LS(N2)  &none  &none  &none  &none  &none  &none  &none  &none
            >;
        };
        layer_Gaming {
            display-name = "Gaming";
            bindings = <
            &kp M  &kp N6  &kp N7  &kp N8  &kp N9  &kp N0  &none  &none  &kp F6  &kp F7  &kp F8  &kp F9  &kp F10  &kp F11
            &kp I  &kp N1  &kp N2  &kp N3  &kp N4  &kp N5  &none  &none  &kp Y  &kp U  &kp I  &kp O  &kp P  &kp F12
            &kp T  &kp TAB  &kp Q  &kp W  &kp E  &kp R  &none  &kp LSHFT  &kp LALT  &kp UP  &kp RET  &none  &kp H  &kp J  &kp K  &kp L  &kp SEMI  &kp SQT
            &kp G  &kp LSHFT  &kp A  &kp S  &kp D  &kp F  &kp V  &kp ESC  &kp N  &kp M  &kp COMMA  &kp DOT  &kp FSLH  &kp BSLH
            &kp B  &kp LCTRL  &kp Z  &kp X  &kp C  &kp SPACE  &kp LCTRL  &kp RET  &kp LEFT  &kp DOWN  &kp RIGHT  &kp MINUS  &kp LBKT  &kp RBKT  &kp EQUAL  &kp GRAVE
            >;
        };
        layer_Lower {
            display-name = "Lower";
            bindings = <
            &trans  &none  &none  &none  &none  &kp HOME  &kp C_BRI_UP  &none  &kp LS(N9)  &kp KP_NUM  &kp EQUAL  &kp KP_SLASH  &kp KP_MULTIPLY  &kp PRINTSCREEN
            &trans  &none  &none  &kp UP_ARROW  &none  &kp END  &kp C_BRI_DN  &none  &kp LS(N0)  &kp KP_N7  &kp KP_N8  &kp KP_N9  &kp KP_MINUS  &kp SCROLLLOCK
            &trans  &none  &kp LEFT_ARROW  &kp DOWN_ARROW  &kp RIGHT_ARROW  &kp PG_UP  &kp PAUSE_BREAK  &trans  &trans  &trans  &trans  &none  &kp LS(N5)  &kp KP_N4  &kp KP_N5  &kp KP_N6  &kp KP_PLUS  &none
            &trans  &kp K_APP  &none  &kp F11  &kp F12  &kp PG_DN  &to 0  &trans  &kp COMMA  &kp KP_N1  &kp KP_N2  &kp KP_N3  &kp KP_ENTER  &trans
            &mo 19  &kp CAPS  &kp INS  &kp F11  &kp F12  &trans  &trans  &trans  &trans  &trans  &trans  &kp KP_N0  &kp KP_N0  &kp KP_DOT  &kp KP_ENTER  &trans
            >;
        };
        layer_LeftIndex {
            display-name = "LeftIndex";
            bindings = <
            &HRM_left_index_tap_v1B_TKZ EQUAL  &HRM_left_index_tap_v1B_TKZ N1  &HRM_left_index_tap_v1B_TKZ N2  &HRM_left_index_tap_v1B_TKZ N3  &HRM_left_index_tap_v1B_TKZ N4  &HRM_left_index_tap_v1B_TKZ N5  &trans  &trans  &trans  &trans  &trans  &trans  &trans  &trans
            &trans  &HRM_left_index_tap_v1B_TKZ Q  &HRM_left_index_tap_v1B_TKZ W  &HRM_left_index_tap_v1B_TKZ E  &HRM_left_index_tap_v1B_TKZ R  &HRM_left_index_tap_v1B_TKZ T  &trans  &trans  &trans  &trans  &trans  &trans  &trans  &trans
            &trans  &HRM_left_index_pinky_v1B_TKZ LCTRL A  &HRM_left_index_ringv1_TKZ LALT S  &HRM_left_index_middy_v1B_TKZ LGUI D  &none  &HRM_left_index_tap_v1B_TKZ G  &trans  &trans  &trans  &trans  &trans  &trans  &trans  &kp J  &kp K  &kp L  &kp SEMI  &trans
            &trans  &HRM_left_index_tap_v1B_TKZ Z  &HRM_left_index_tap_v1B_TKZ X  &HRM_left_index_tap_v1B_TKZ C  &HRM_left_index_tap_v1B_TKZ V  &HRM_left_index_tap_v1B_TKZ B  &trans  &trans  &trans  &trans  &trans  &trans  &trans  &trans
            &trans  &trans  &trans  &trans  &trans  &trans  &trans  &trans  &trans  &trans  &trans  &trans  &trans  &trans  &trans  &trans
            >;
        };
        layer_LeftMiddy {
            display-name = "LeftMiddy";
            bindings = <
            &HRM_left_middy_tap_v1B_TKZ EQUAL  &HRM_left_middy_tap_v1B_TKZ N1  &HRM_left_middy_tap_v1B_TKZ N2  &HRM_left_middy_tap_v1B_TKZ N3  &HRM_left_middy_tap_v1B_TKZ N4  &HRM_left_middy_tap_v1B_TKZ N5  &trans  &trans  &trans  &trans  &trans  &trans  &trans  &trans
            &trans  &HRM_left_middy_tap_v1B_TKZ Q  &HRM_left_middy_tap_v1B_TKZ W  &HRM_left_middy_tap_v1B_TKZ E  &HRM_left_middy_tap_v1B_TKZ R  &HRM_left_middy_tap_v1B_TKZ T  &trans  &trans  &trans  &trans  &trans  &trans  &trans  &trans
            &trans  &HRM_left_middy_pinky_v1B_TKZ LCTRL A  &HRM_left_middy_ring_v1B_TKZ LALT S  &none  &HRM_left_middy_index_v1B_TKZ LSHFT F  &HRM_left_middy_tap_v1B_TKZ G  &trans  &trans  &trans  &trans  &trans  &trans  &trans  &kp J  &kp K  &kp L  &kp SEMI  &trans
            &trans  &HRM_left_middy_tap_v1B_TKZ Z  &HRM_left_middy_tap_v1B_TKZ X  &HRM_left_middy_tap_v1B_TKZ C  &HRM_left_middy_tap_v1B_TKZ V  &HRM_left_middy_tap_v1B_TKZ B  &trans  &trans  &trans  &trans  &trans  &trans  &trans  &trans
            &trans  &trans  &trans  &trans  &trans  &trans  &trans  &trans  &trans  &trans  &trans  &trans  &trans  &trans  &trans  &trans
            >;
        };
        layer_LeftRingy {
            display-name = "LeftRingy";
            bindings = <
            &HRM_left_ring_tap_v1B_TKZ EQUAL  &HRM_left_ring_tap_v1B_TKZ N1  &HRM_left_ring_tap_v1B_TKZ N2  &HRM_left_ring_tap_v1B_TKZ N3  &HRM_left_ring_tap_v1B_TKZ N4  &HRM_left_ring_tap_v1B_TKZ N5  &trans  &trans  &trans  &trans  &trans  &trans  &trans  &trans
            &trans  &HRM_left_ring_tap_v1B_TKZ Q  &HRM_left_ring_tap_v1B_TKZ W  &HRM_left_ring_tap_v1B_TKZ E  &HRM_left_ring_tap_v1B_TKZ R  &HRM_left_ring_tap_v1B_TKZ T  &trans  &trans  &trans  &trans  &trans  &trans  &trans  &trans
            &trans  &HRM_left_ring_pinky_v1B_TKZ LCTRL A  &none  &HRM_left_ring_middy_v1B_TKZ LGUI D  &HRM_left_ring_index_v1B_TKZ LSHFT F  &HRM_left_ring_tap_v1B_TKZ G  &trans  &trans  &trans  &trans  &trans  &trans  &trans  &kp J  &kp K  &kp L  &kp SEMI  &trans
            &trans  &HRM_left_ring_tap_v1B_TKZ Z  &HRM_left_ring_tap_v1B_TKZ X  &HRM_left_ring_tap_v1B_TKZ C  &HRM_left_ring_tap_v1B_TKZ V  &HRM_left_ring_tap_v1B_TKZ B  &trans  &trans  &trans  &trans  &trans  &trans  &trans  &trans
            &trans  &trans  &trans  &trans  &trans  &trans  &trans  &trans  &trans  &trans  &trans  &trans  &trans  &trans  &trans  &trans
            >;
        };
        layer_LeftPinky {
            display-name = "LeftPinky";
            bindings = <
            &HRM_left_pinky_tap_v1B_TKZ EQUAL  &HRM_left_pinky_tap_v1B_TKZ N1  &HRM_left_pinky_tap_v1B_TKZ N2  &HRM_left_pinky_tap_v1B_TKZ N3  &HRM_left_pinky_tap_v1B_TKZ N4  &HRM_left_pinky_tap_v1B_TKZ N5  &trans  &trans  &trans  &trans  &trans  &trans  &trans  &trans
            &trans  &HRM_left_pinky_tap_v1B_TKZ Q  &HRM_left_pinky_tap_v1B_TKZ W  &HRM_left_pinky_tap_v1B_TKZ E  &HRM_left_pinky_tap_v1B_TKZ R  &HRM_left_pinky_tap_v1B_TKZ T  &trans  &trans  &trans  &trans  &trans  &trans  &trans  &trans
            &trans  &none  &HRM_left_pinky_ring_v1B_TKZ LALT S  &HRM_left_pinky_middy_v1B_TKZ LGUI D  &HRM_left_pinky_index_v1B_TKZ LSHFT F  &HRM_left_pinky_tap_v1B_TKZ G  &trans  &trans  &trans  &trans  &trans  &trans  &trans  &kp J  &kp K  &kp L  &kp SEMI  &trans
            &trans  &HRM_left_pinky_tap_v1B_TKZ Z  &HRM_left_pinky_tap_v1B_TKZ X  &HRM_left_pinky_tap_v1B_TKZ C  &HRM_left_pinky_tap_v1B_TKZ V  &HRM_left_pinky_tap_v1B_TKZ B  &trans  &trans  &trans  &trans  &trans  &trans  &trans  &trans
            &trans  &trans  &trans  &trans  &trans  &trans  &trans  &trans  &trans  &trans  &trans  &trans  &trans  &trans  &trans  &trans
            >;
        };
        layer_RightIndex {
            display-name = "RightIndex";
            bindings = <
            &trans  &trans  &trans  &trans  &trans  &trans  &trans  &trans  &HRM_right_index_tap_v1B_TKZ N6  &HRM_right_index_tap_v1B_TKZ N7  &HRM_right_index_tap_v1B_TKZ N8  &HRM_right_index_tap_v1B_TKZ N9  &HRM_right_index_tap_v1B_TKZ N0  &HRM_right_index_tap_v1B_TKZ MINUS
            &trans  &trans  &trans  &trans  &trans  &trans  &trans  &trans  &HRM_right_index_tap_v1B_TKZ Y  &HRM_right_index_tap_v1B_TKZ U  &HRM_right_index_tap_v1B_TKZ I  &HRM_right_index_tap_v1B_TKZ O  &HRM_right_index_tap_v1B_TKZ P  &HRM_right_index_tap_v1B_TKZ BSLH
            &trans  &kp A  &kp S  &kp D  &kp F  &trans  &trans  &trans  &trans  &trans  &trans  &trans  &HRM_right_index_tap_v1B_TKZ H  &none  &HRM_right_index_middy_v1B_TKZ RGUI K  &HRM_right_index_ring_v1B_TKZ LALT L  &HRM_right_index_pinky_v1B_TKZ LCTRL SEMI  &HRM_right_index_tap_v1B_TKZ SQT
            &trans  &trans  &trans  &trans  &trans  &trans  &trans  &trans  &HRM_right_index_tap_v1B_TKZ N  &HRM_right_index_tap_v1B_TKZ M  &HRM_right_index_tap_v1B_TKZ COMMA  &HRM_right_index_tap_v1B_TKZ DOT  &trans  &trans
            &trans  &trans  &trans  &trans  &trans  &trans  &trans  &trans  &trans  &trans  &trans  &trans  &trans  &trans  &trans  &trans
            >;
        };
        layer_RightMiddy {
            display-name = "RightMiddy";
            bindings = <
            &trans  &trans  &trans  &trans  &trans  &trans  &trans  &trans  &HRM_right_middy_tap_v1B_TKZ N6  &HRM_right_middy_tap_v1B_TKZ N7  &HRM_right_middy_tap_v1B_TKZ N8  &HRM_right_middy_tap_v1B_TKZ N9  &HRM_right_middy_tap_v1B_TKZ N0  &HRM_right_middy_tap_v1B_TKZ MINUS
            &trans  &trans  &trans  &trans  &trans  &trans  &trans  &trans  &HRM_right_middy_tap_v1B_TKZ Y  &HRM_right_middy_tap_v1B_TKZ U  &HRM_right_middy_tap_v1B_TKZ I  &HRM_right_middy_tap_v1B_TKZ O  &HRM_right_middy_tap_v1B_TKZ P  &HRM_right_middy_tap_v1B_TKZ BSLH
            &trans  &kp A  &kp S  &kp D  &kp F  &trans  &trans  &trans  &trans  &trans  &trans  &trans  &HRM_right_middy_tap_v1B_TKZ H  &HRM_right_middy_index_v1B_TKZ RSHFT J  &none  &HRM_right_middy_ring_v1B_TKZ LALT L  &HRM_right_middy_pinky_v1B_TKZ RCTRL SEMI  &HRM_right_middy_tap_v1B_TKZ SQT
            &trans  &trans  &trans  &trans  &trans  &trans  &trans  &trans  &HRM_right_middy_tap_v1B_TKZ N  &HRM_right_middy_tap_v1B_TKZ M  &HRM_right_middy_tap_v1B_TKZ COMMA  &HRM_right_middy_tap_v1B_TKZ DOT  &trans  &trans
            &trans  &trans  &trans  &trans  &trans  &trans  &trans  &trans  &trans  &trans  &trans  &trans  &trans  &trans  &trans  &trans
            >;
        };
        layer_RightRingy {
            display-name = "RightRingy";
            bindings = <
            &trans  &trans  &trans  &trans  &trans  &trans  &trans  &trans  &HRM_right_ring_tap_v1B_TKZ N6  &HRM_right_ring_tap_v1B_TKZ N7  &HRM_right_ring_tap_v1B_TKZ N8  &HRM_right_ring_tap_v1B_TKZ N9  &HRM_right_ring_tap_v1B_TKZ N0  &HRM_right_ring_tap_v1B_TKZ MINUS
            &trans  &trans  &trans  &trans  &trans  &trans  &trans  &trans  &HRM_right_ring_tap_v1B_TKZ Y  &HRM_right_ring_tap_v1B_TKZ U  &HRM_right_ring_tap_v1B_TKZ I  &HRM_right_ring_tap_v1B_TKZ O  &HRM_right_ring_tap_v1B_TKZ P  &HRM_right_ring_tap_v1B_TKZ BSLH
            &trans  &kp A  &kp S  &kp D  &kp F  &trans  &trans  &trans  &trans  &trans  &trans  &trans  &HRM_right_ring_tap_v1B_TKZ H  &HRM_right_ring_index_v1B_TKZ RSHFT J  &HRM_right_ring_middy_v1B_TKZ RGUI K  &none  &HRM_right_ring_pinky_v1B_TKZ RCTRL SEMI  &HRM_right_ring_tap_v1B_TKZ SQT
            &trans  &trans  &trans  &trans  &trans  &trans  &trans  &trans  &HRM_right_ring_tap_v1B_TKZ N  &HRM_right_ring_tap_v1B_TKZ M  &HRM_right_ring_tap_v1B_TKZ COMMA  &HRM_right_ring_tap_v1B_TKZ DOT  &trans  &trans
            &trans  &trans  &trans  &trans  &trans  &trans  &trans  &trans  &trans  &trans  &trans  &trans  &trans  &trans  &trans  &trans
            >;
        };
        layer_RightPinky {
            display-name = "RightPinky";
            bindings = <
            &trans  &trans  &trans  &trans  &trans  &trans  &trans  &trans  &HRM_right_pinky_tap_v1B_TKZ N6  &HRM_right_pinky_tap_v1B_TKZ N7  &HRM_right_pinky_tap_v1B_TKZ N8  &HRM_right_pinky_tap_v1B_TKZ N9  &HRM_right_pinky_tap_v1B_TKZ N0  &HRM_right_pinky_tap_v1B_TKZ MINUS
            &trans  &trans  &trans  &trans  &trans  &trans  &trans  &trans  &HRM_right_pinky_tap_v1B_TKZ Y  &HRM_right_pinky_tap_v1B_TKZ U  &HRM_right_pinky_tap_v1B_TKZ I  &HRM_right_pinky_tap_v1B_TKZ O  &HRM_right_pinky_tap_v1B_TKZ P  &HRM_right_pinky_tap_v1B_TKZ BSLH
            &trans  &kp A  &kp S  &kp D  &kp F  &trans  &trans  &trans  &trans  &trans  &trans  &trans  &HRM_right_pinky_tap_v1B_TKZ H  &HRM_right_pinky_index_v1B_TKZ RSHFT J  &HRM_right_pinky_middy_v1B_TKZ RGUI K  &HRM_right_pinky_ring_v1B_TKZ LALT L  &none  &HRM_right_pinky_tap_v1B_TKZ SQT
            &trans  &trans  &trans  &trans  &trans  &trans  &trans  &trans  &HRM_right_pinky_tap_v1B_TKZ N  &HRM_right_pinky_tap_v1B_TKZ M  &HRM_right_pinky_tap_v1B_TKZ COMMA  &HRM_right_pinky_tap_v1B_TKZ DOT  &trans  &trans
            &trans  &trans  &trans  &trans  &trans  &trans  &trans  &trans  &trans  &trans  &trans  &trans  &trans  &trans  &trans  &trans
            >;
        };
        layer_Mouse {
            display-name = "Mouse";
            bindings = <
            &none  &none  &none  &none  &none  &none  &none  &none  &none  &none  &none  &none  &none  &none
            &none  &none  &msc SCRL_LEFT  &mmv MOVE_UP  &msc SCRL_RIGHT  &none  &none  &none  &none  &sk RSHFT  &sk RGUI  &sk RALT  &sk RCTRL  &none
            &none  &msc SCRL_UP  &mmv MOVE_LEFT  &mmv MOVE_DOWN  &mmv MOVE_RIGHT  &msc SCRL_UP  &none  &mkp MCLK  &kp K_APP  &kp LG(C)  &kp LG(V)  &none  &msc SCRL_UP  &mo 17  &mo 18  &mo 16  &mkp LCLK  &mkp MB4
            &none  &msc SCRL_DOWN  &mo 16  &mo 18  &mo 17  &msc SCRL_DOWN  &mkp MB5  &kp LG(X)  &msc SCRL_DOWN  &msc SCRL_LEFT  &mmv MOVE_UP  &msc SCRL_RIGHT  &mkp RCLK  &mkp MB5
            &none  &none  &none  &none  &none  &mkp LCLK  &mkp RCLK  &mkp MB4  &none  &none  &none  &mmv MOVE_LEFT  &mmv MOVE_DOWN  &mmv MOVE_RIGHT  &mkp MCLK  &kp K_APP
            >;
        };
        layer_MouseSlow {
            display-name = "MouseSlow";
            bindings = <
            &trans  &trans  &trans  &trans  &trans  &trans  &trans  &trans  &trans  &trans  &trans  &trans  &trans  &trans
            &trans  &trans  &trans  &trans  &trans  &trans  &trans  &trans  &trans  &trans  &trans  &trans  &trans  &trans
            &trans  &trans  &trans  &trans  &trans  &trans  &trans  &trans  &trans  &trans  &trans  &trans  &trans  &trans  &trans  &trans  &trans  &trans
            &trans  &trans  &trans  &trans  &trans  &trans  &trans  &trans  &trans  &trans  &trans  &trans  &trans  &trans
            &trans  &trans  &trans  &trans  &trans  &trans  &trans  &trans  &trans  &trans  &trans  &trans  &trans  &trans  &trans  &trans
            >;
        };
        layer_MouseFast {
            display-name = "MouseFast";
            bindings = <
            &trans  &trans  &trans  &trans  &trans  &trans  &trans  &trans  &trans  &trans  &trans  &trans  &trans  &trans
            &trans  &trans  &trans  &trans  &trans  &trans  &trans  &trans  &trans  &trans  &trans  &trans  &trans  &trans
            &trans  &trans  &trans  &trans  &trans  &trans  &trans  &trans  &trans  &trans  &trans  &trans  &trans  &trans  &trans  &trans  &trans  &trans
            &trans  &trans  &trans  &trans  &trans  &trans  &trans  &trans  &trans  &trans  &trans  &trans  &trans  &trans
            &trans  &trans  &trans  &trans  &trans  &trans  &trans  &trans  &trans  &trans  &trans  &trans  &trans  &trans  &trans  &trans
            >;
        };
        layer_MouseWarp {
            display-name = "MouseWarp";
            bindings = <
            &trans  &trans  &trans  &trans  &trans  &trans  &trans  &trans  &trans  &trans  &trans  &trans  &trans  &trans
            &trans  &trans  &trans  &trans  &trans  &trans  &trans  &trans  &trans  &trans  &trans  &trans  &trans  &trans
            &trans  &trans  &trans  &trans  &trans  &trans  &trans  &trans  &trans  &trans  &trans  &trans  &trans  &trans  &trans  &trans  &trans  &trans
            &trans  &trans  &trans  &trans  &trans  &trans  &trans  &trans  &trans  &trans  &trans  &trans  &trans  &trans
            &trans  &trans  &trans  &trans  &trans  &trans  &trans  &trans  &trans  &trans  &trans  &trans  &trans  &trans  &trans  &trans
            >;
        };
        layer_Magic {
            display-name = "Magic";
            bindings = <
            &to 0  &to 5  &to 1  &none  &none  &none  &none  &bt BT_CLR  &none  &none  &none  &none  &none  &none
            &none  &rgb_ug RGB_SPI  &rgb_ug RGB_SAI  &rgb_ug RGB_HUI  &rgb_ug RGB_BRI  &rgb_ug RGB_TOG  &none  &bt BT_CLR_ALL  &none  &none  &none  &none  &none  &none
            &bootloader  &rgb_ug RGB_SPD  &rgb_ug RGB_SAD  &rgb_ug RGB_HUD  &rgb_ug RGB_BRD  &rgb_ug RGB_EFF  &none  &bt_2  &bt_3  &none  &none  &stp STP_BAT  &none  &none  &none  &none  &none  &bootloader
            &sys_reset  &none  &none  &none  &none  &none  &bt_4  &none  &none  &none  &none  &none  &none  &sys_reset
            &none  &none  &none  &none  &none  &bt_0  &bt_1  &out OUT_USB  &none  &none  &none  &none  &none  &none  &none  &none
            >;
        };
    };
};
